# max32662 register map
Vendor: Maxim-Integrated; Series: ARMCM4; File version: 1.1
CPU: CM4 r2p1, little endian, MPU, FPU, 3 interrupt priority bits
Registers are 32-bit, read-write, reset 0x0 unless marked. A register's access mark holds for its fields unless they carry their own. Offsets are from the block's base; [hi:lo] are bit positions; {n}, {i} and the like mark numbered series; 'fields as' and 'values as' point back to an identical list.

## FCR — Function Control Register.
Base 0x40000800
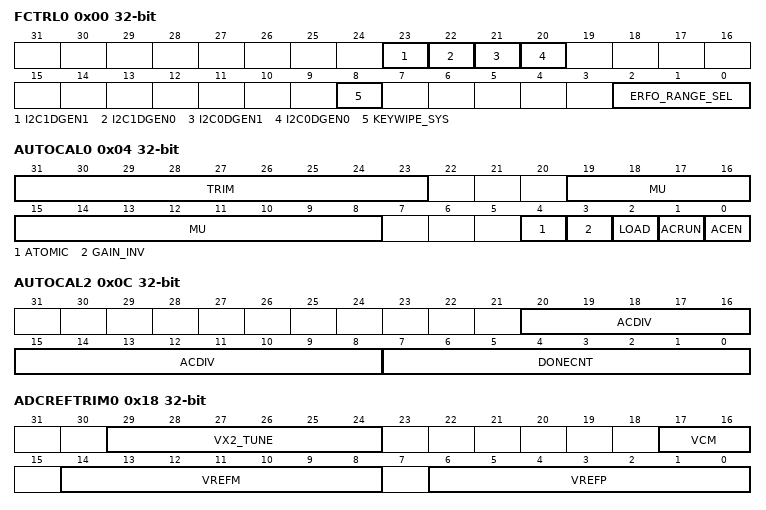
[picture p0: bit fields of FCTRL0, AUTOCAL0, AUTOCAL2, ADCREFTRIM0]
0x00 FCTRL0 — Function Control 0.
  [23] I2C1DGEN1 — I2C1 SCL Pad Deglitcher enable.
    0=dis (Deglitcher disabled.); 1=en (Deglitcher enabled.)
  [22] I2C1DGEN0 — I2C1 SDA Pad Deglitcher enable.
    0=dis (Deglitcher disabled.); 1=en (Deglitcher enabled.)
  [21] I2C0DGEN1 — I2C0 SCL Pad Deglitcher enable.
    0=dis (Deglitcher disabled.); 1=en (Deglitcher enabled.)
  [20] I2C0DGEN0 — I2C0 SDA Pad Deglitcher enable.
    0=dis (Deglitcher disabled.); 1=en (Deglitcher enabled.)
  [8] KEYWIPE_SYS — Wipe System AES Key Register.
  [2:0] ERFO_RANGE_SEL — ERFO Frequency Range Select. Control ibias_gm_stage.
0x04 AUTOCAL0 — Automatic Calibration 0.
  [31:23] TRIM — HIRC96M Trim Value determinged by Auto Calibration.
  [19:8] MU — Adaptation Gain Value.
  [4] ATOMIC — Start atomic autocal.
    0=not (Not Running.); 1=run (Running.)
  [3] GAIN_INV — Invert Gain.
    0=not (Not inverted.); 1=Inverted
  [2] LOAD — Load Trim.
  [1] ACRUN — Autocalibration Run.
    0=not (Not Running.); 1=run (Running.)
  [0] ACEN — Auto-calibration Enable for HIRC96M.
    0=dis (Disabled.); 1=en (Enabled.)
0x08 AUTOCAL1 — Automatic Calibration 1.
  [8:0] INITTRIM — Initial Trim Setting fir HIRC96M Auto Calibration procedure.
0x0C AUTOCAL2 — Automatic Calibration 2
  [20:8] ACDIV — Auto-callibration Divide Factor.
  [7:0] DONECNT — Auto-callibration Done Counter Setting.
0x18 ADCREFTRIM0 — ADC Reference Trim 0 Control Register.
  [29:24] VX2_TUNE — COntrols tuning capacitor in fine DAC, offset binary.
  [17:16] VCM — Trimming code for VCM output of reference buffer.
  [14:8] VREFM — Trimming code for VREFM output of reference buffer.
  [6:0] VREFP — Trimming code for VREFP output of reference buffer.
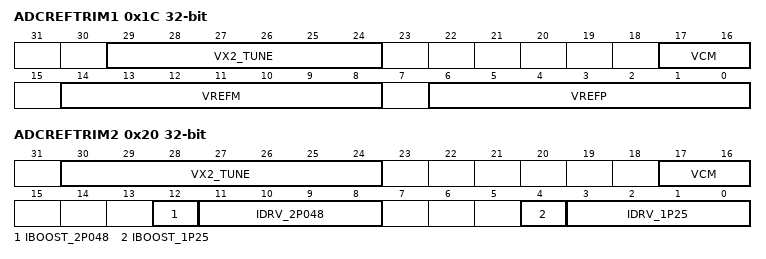
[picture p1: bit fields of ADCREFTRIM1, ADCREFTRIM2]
0x1C ADCREFTRIM1 — ADC Reference Trim 1 Control Register.
  fields as ADCREFTRIM0
0x20 ADCREFTRIM2 — ADC Reference Trim 2 Control Register.
  [30:24] VX2_TUNE — Controls tuning capacitor in fine DAC, offset binary.
  [17:16] VCM — Trimming code for VCM output of reference buffer.
  [12] IBOOST_2P048 — Trimming value for extra drive current in reference buffer outputs, 2.048V Reference.
  [11:8] IDRV_2P048 — Trimming code for reference buffer drive strength, 2.048V Reference.
  [4] IBOOST_1P25 — Trimming value for extra drive current in reference buffer outputsm 1.25V Reference.
  [3:0] IDRV_1P25 — Trimming code for reference buffer drive strength, 1.25V Reference.
0x24 ERFOKS — ERFO Kick Start Control Register.
  [15:0] CTRL — Kickstart Control for ERFO (XO32M)

## FLC — Flash Memory Control.
Base 0x40029000; register names take the prefix FLSH_
0x00 ADDR — Flash Write Address.
  [31:0] ADDR — Address for next operation.
0x04 CLKDIV reset 0x64 — Flash Clock Divide. The clock (PLL0) is divided by this value to generate a 1 MHz clock for Flash controller.
  [7:0] CLKDIV — Flash Clock Divide. The clock is divided by this value to generate a 1MHz clock for flash controller.
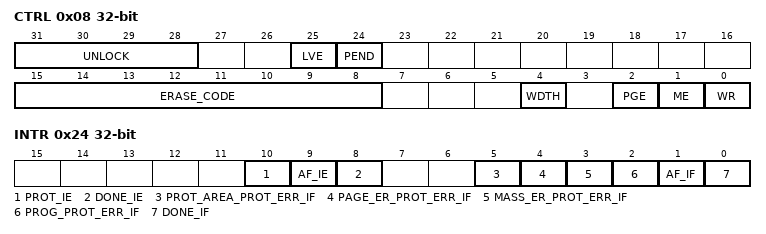
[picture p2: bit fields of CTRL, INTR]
0x08 CTRL — Flash Control Register.
  [31:28] UNLOCK — Flash Unlock. The correct unlock code must be written to these four bits before any Flash write or erase operation is allowed.
    2=unlocked (Flash Unlocked.); 3=locked (Flash Locked.)
  [25] LVE — Low Voltage enable.
  [24] PEND ro — Flash Pending. When Flash operation is in progress (busy), Flash reads and writes will fail. When PEND is set, write to all Flash registers, with exception of the Flash interrupt register, are ignored.
    0=idle; 1=busy
  [15:8] ERASE_CODE — Erase Code. The ERASE_CODE must be set up property before erase operation can be initiated. These bits are automatically cleared after the operation is complete.
    0=nop (No operation.); 85=erasePage (Enable Page Erase.); 170=eraseAll (Enable Mass Erase. The debug port must be enabled.)
  [4] WDTH
  [2] PGE — Page Erase. This bit is automatically cleared after the operation.
    0=complete (No operation/complete.); 1=Start operation
  [1] ME — Mass Erase. This bit is automatically cleared after the operation.
    0=complete (No operation/complete.); 1=Start operation
  [0] WR — Write. This bit is automatically cleared after the operation.
    0=complete (No operation/complete.); 1=Start operation
0x24 INTR — Flash Interrupt Register.
  [10] PROT_IE
    0=dis (Disable.); 1=en (Enable.)
  [9] AF_IE
    0=dis (Disable.); 1=en (Enable.)
  [8] DONE_IE — Flash Done Interrupt Enable.
    0=dis (Disable.); 1=en (Enable.)
  [5] PROT_AREA_PROT_ERR_IF
    0=noerr (No Failure.); 1=error (Failure occurs.)
  [4] PAGE_ER_PROT_ERR_IF
    0=noerr (No Failure.); 1=error (Failure occurs.)
  [3] MASS_ER_PROT_ERR_IF
    0=noerr (No Failure.); 1=error (Failure occurs.)
  [2] PROG_PROT_ERR_IF — Program Protection Error.
    0=noerr (No Failure.); 1=error (Failure occurs.)
  [1] AF_IF — Flash Access Fail. This bit is set when an attempt is made to write the flash while the flash is busy or the flash is locked. This bit can only be set to 1 by hardware.
    0=noerr (No Failure.); 1=error (Failure occurs.)
  [0] DONE_IF — Flash Done Interrupt. This bit is set to 1 upon Flash write or erase completion.
    0=inactive (No interrupt is pending.); 1=pending (An interrupt is pending.)
{0x30+4i} DATA[{i}] (i=0..3) — Flash Write Data.
  [31:0] DATA — Data next operation.
0x40 ACTRL wo — Access Control Register. Writing the ACNTL register with the following values in the order shown, allows read and write access to the system and user Information block: pflc-acntl = 0x3a7f5ca3; pflc-acntl = 0xa1e34f20; pflc-acntl = 0x9608b2c1. When unlocked, a write of any word will disable access to system and user information block. Readback of this register is always zero.
  [31:0] ACTRL — Access control.
{0x80+8i} WELR{i} (i=0..5) — Access control.
{0x84+8i} RLR{i} (i=0..5) — Access control.
